VERSION ""

NS_ :

BS_:

BU_:

BO_ 3221225472 VECTOR__INDEPENDENT_SIG_MSG: 0 Vector__XXX
 SG_ OmegaX : 32|32@1- (1,0) [0|0] "rad" Vector__XXX
 SG_ volt2 : 15|16@0+ (0.1,0) [0|0] "mV" Vector__XXX
 SG_ volt3 : 31|16@0+ (0.1,0) [0|0] "mV" Vector__XXX
 SG_ volt4 : 46|16@0+ (0.1,0) [0|0] "mV" Vector__XXX
 SG_ NewSignal_0033 : 8|8@1+ (1,0) [0|0] "" Vector__XXX
 SG_ OmegaY : 0|32@1- (1,0) [0|0] "rad/s" Vector__XXX
 SG_ OmegaZ : 32|32@1- (1,0) [0|0] "rad/s" Vector__XXX
 SG_ AccZ : 0|32@1- (1,0) [0|0] "m/s^2" Vector__XXX
 SG_ OmegaX : 32|32@1- (1,0) [0|0] "rad/s" Vector__XXX
 SG_ AccX : 0|32@1- (1,0) [0|0] "m/s^2" Vector__XXX
 SG_ AccY : 32|32@1- (1,0) [0|0] "m/s^2" Vector__XXX
 SG_ SuspFL : 0|10@1+ (1,0) [0|0] "mm" Vector__XXX
 SG_ SuspFR : 10|10@1+ (1,0) [0|0] "mm" Vector__XXX
 SG_ SuspRL : 20|10@1+ (1,0) [0|0] "mm" Vector__XXX
 SG_ SuspRR : 30|10@1+ (1,0) [0|0] "mm" Vector__XXX
 SG_ Temp4 : 0|16@1+ (1,0) [0|0] "C" Vector__XXX
 SG_ Temp5 : 16|16@1+ (1,0) [0|0] "C" Vector__XXX
 SG_ Temp6 : 32|16@1+ (1,0) [0|0] "C" Vector__XXX
 SG_ Temp7 : 48|16@1+ (1,0) [0|0] "C" Vector__XXX
 SG_ Temp0 : 0|16@1+ (1,0) [0|0] "C" Vector__XXX
 SG_ Temp1 : 16|16@1+ (1,0) [0|0] "C" Vector__XXX
 SG_ Temp2 : 32|16@1+ (1,0) [0|0] "C" Vector__XXX
 SG_ Temp3 : 48|16@1+ (1,0) [0|0] "C" Vector__XXX

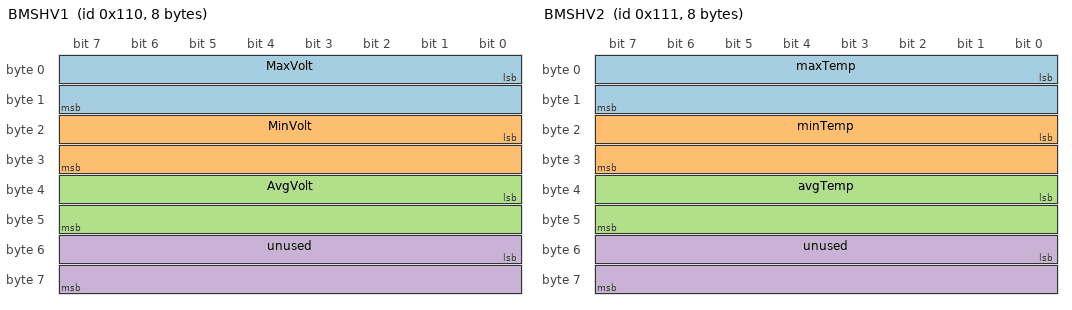
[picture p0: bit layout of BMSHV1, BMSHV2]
BO_ 272 BMSHV1: 8 Vector__XXX
 SG_ MaxVolt : 0|16@1+ (0.1,0) [0|0] "mV" Vector__XXX
 SG_ MinVolt : 16|16@1+ (0.1,0) [0|0] "mV" Vector__XXX
 SG_ AvgVolt : 32|16@1+ (0.1,0) [0|0] "mV" Vector__XXX
 SG_ unused : 48|16@1+ (1,0) [0|0] "" Vector__XXX

BO_ 273 BMSHV2: 8 Vector__XXX
 SG_ maxTemp : 0|16@1+ (1,0) [0|0] "C" Vector__XXX
 SG_ minTemp : 16|16@1+ (1,0) [0|0] "C" Vector__XXX
 SG_ avgTemp : 32|16@1+ (1,0) [0|0] "C" Vector__XXX
 SG_ unused : 48|16@1+ (1,0) [0|0] "" Vector__XXX

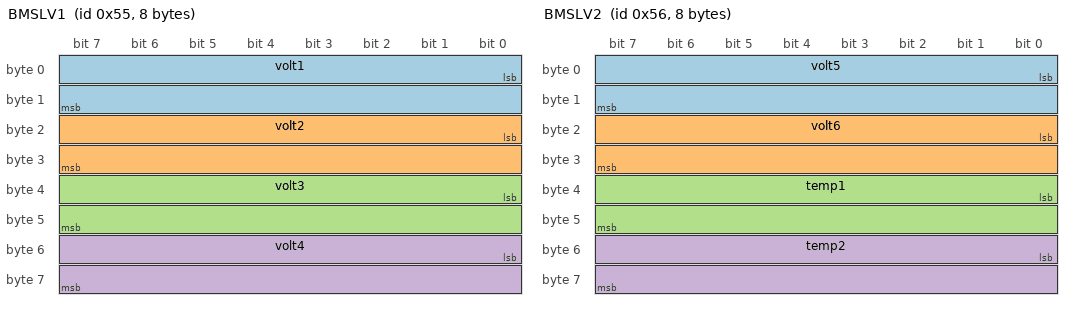
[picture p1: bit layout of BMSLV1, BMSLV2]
BO_ 85 BMSLV1: 8 Vector__XXX
 SG_ volt1 : 0|16@1+ (0.1,0) [0|0] "mV" Vector__XXX
 SG_ volt2 : 16|16@1+ (0.1,0) [0|0] "mV" Vector__XXX
 SG_ volt3 : 32|16@1+ (0.1,0) [0|0] "mV" Vector__XXX
 SG_ volt4 : 48|16@1+ (0.1,0) [0|0] "mV" Vector__XXX

BO_ 86 BMSLV2: 8 Vector__XXX
 SG_ volt5 : 0|16@1+ (0.1,0) [0|0] "mV" Vector__XXX
 SG_ volt6 : 16|16@1+ (0.1,0) [0|0] "mV" Vector__XXX
 SG_ temp1 : 32|16@1+ (0.001,0) [0|0] "C" Vector__XXX
 SG_ temp2 : 48|16@1+ (0.001,0) [0|0] "C" Vector__XXX

BO_ 962 LEM: 4 Vector__XXX
 SG_ curr : 7|32@0+ (1,0) [0|0] "mA" Vector__XXX

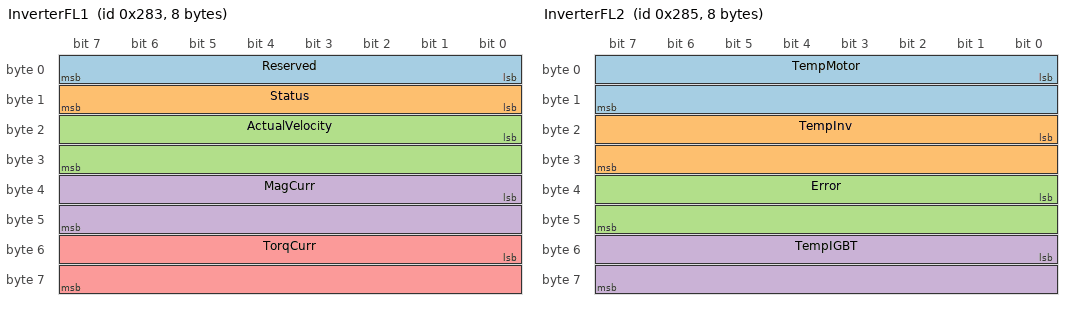
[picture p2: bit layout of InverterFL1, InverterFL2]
BO_ 643 InverterFL1: 8 Vector__XXX
 SG_ Reserved : 0|8@1+ (1,0) [0|0] "" Vector__XXX
 SG_ Status : 8|8@1+ (1,0) [0|0] "" Vector__XXX
 SG_ ActualVelocity : 16|16@1+ (1,0) [0|0] "" Vector__XXX
 SG_ MagCurr : 32|16@1+ (1,0) [0|0] "" Vector__XXX
 SG_ TorqCurr : 48|16@1+ (1,0) [0|0] "" Vector__XXX

BO_ 645 InverterFL2: 8 Vector__XXX
 SG_ TempMotor : 0|16@1+ (1,0) [0|0] "" Vector__XXX
 SG_ TempInv : 16|16@1+ (1,0) [0|0] "" Vector__XXX
 SG_ Error : 32|16@1+ (1,0) [0|0] "" Vector__XXX
 SG_ TempIGBT : 48|16@1+ (1,0) [0|0] "" Vector__XXX

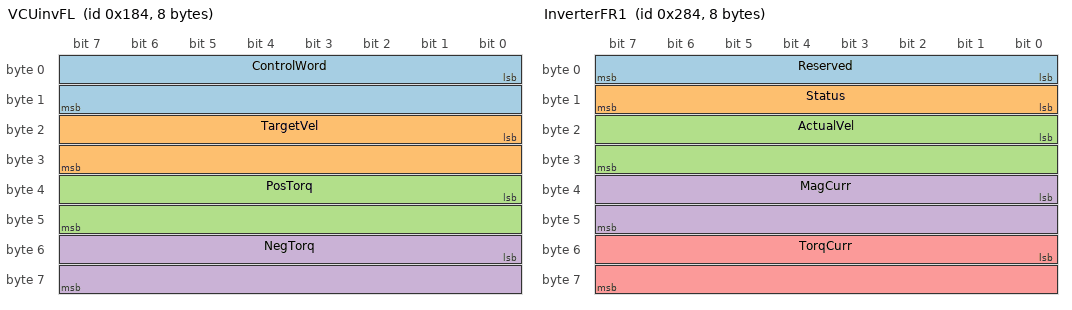
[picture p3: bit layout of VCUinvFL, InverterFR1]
BO_ 388 VCUinvFL: 8 Vector__XXX
 SG_ ControlWord : 0|16@1+ (1,0) [0|0] "" Vector__XXX
 SG_ TargetVel : 16|16@1+ (1,0) [0|0] "" Vector__XXX
 SG_ PosTorq : 32|16@1+ (1,0) [0|0] "" Vector__XXX
 SG_ NegTorq : 48|16@1+ (1,0) [0|0] "" Vector__XXX

BO_ 644 InverterFR1: 8 Vector__XXX
 SG_ Reserved : 0|8@1+ (1,0) [0|0] "" Vector__XXX
 SG_ Status : 8|8@1+ (1,0) [0|0] "" Vector__XXX
 SG_ ActualVel : 16|16@1+ (1,0) [0|0] "" Vector__XXX
 SG_ MagCurr : 32|16@1+ (1,0) [0|0] "" Vector__XXX
 SG_ TorqCurr : 48|16@1+ (1,0) [0|0] "" Vector__XXX

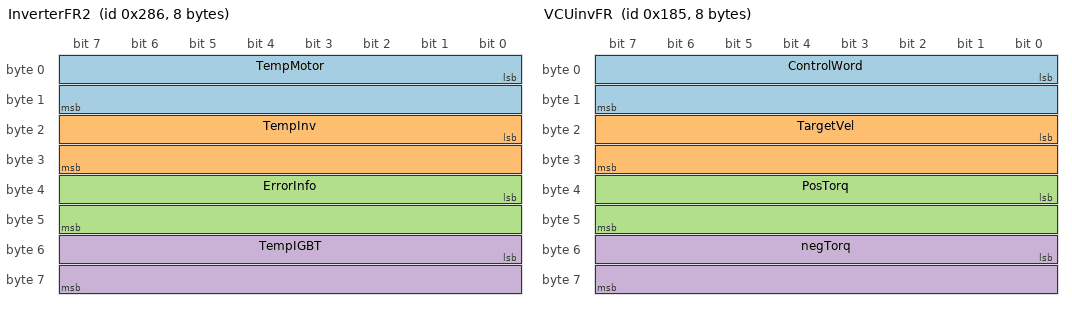
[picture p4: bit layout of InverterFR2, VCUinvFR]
BO_ 646 InverterFR2: 8 Vector__XXX
 SG_ TempMotor : 0|16@1+ (1,0) [0|0] "" Vector__XXX
 SG_ TempInv : 16|16@1+ (1,0) [0|0] "" Vector__XXX
 SG_ ErrorInfo : 32|16@1+ (1,0) [0|0] "" Vector__XXX
 SG_ TempIGBT : 48|16@1+ (1,0) [0|0] "" Vector__XXX

BO_ 389 VCUinvFR: 8 Vector__XXX
 SG_ ControlWord : 0|16@1+ (1,0) [0|0] "" Vector__XXX
 SG_ TargetVel : 16|16@1+ (1,0) [0|0] "" Vector__XXX
 SG_ PosTorq : 32|16@1+ (1,0) [0|0] "" Vector__XXX
 SG_ negTorq : 48|16@1+ (1,0) [0|0] "" Vector__XXX

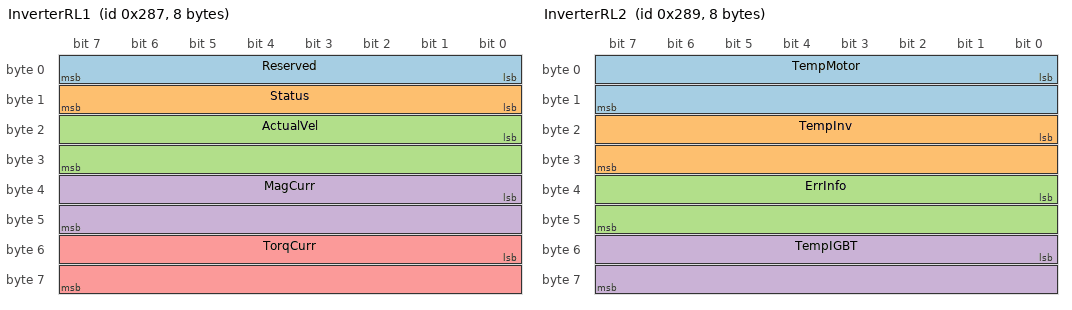
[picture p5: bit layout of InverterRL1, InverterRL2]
BO_ 647 InverterRL1: 8 Vector__XXX
 SG_ Reserved : 0|8@1+ (1,0) [0|0] "" Vector__XXX
 SG_ Status : 8|8@1+ (1,0) [0|0] "" Vector__XXX
 SG_ ActualVel : 16|16@1+ (1,0) [0|0] "" Vector__XXX
 SG_ MagCurr : 32|16@1+ (1,0) [0|0] "" Vector__XXX
 SG_ TorqCurr : 48|16@1+ (1,0) [0|0] "" Vector__XXX

BO_ 649 InverterRL2: 8 Vector__XXX
 SG_ TempMotor : 0|16@1+ (1,0) [0|0] "" Vector__XXX
 SG_ TempInv : 16|16@1+ (1,0) [0|0] "" Vector__XXX
 SG_ ErrInfo : 32|16@1+ (1,0) [0|0] "" Vector__XXX
 SG_ TempIGBT : 48|16@1+ (1,0) [0|0] "" Vector__XXX

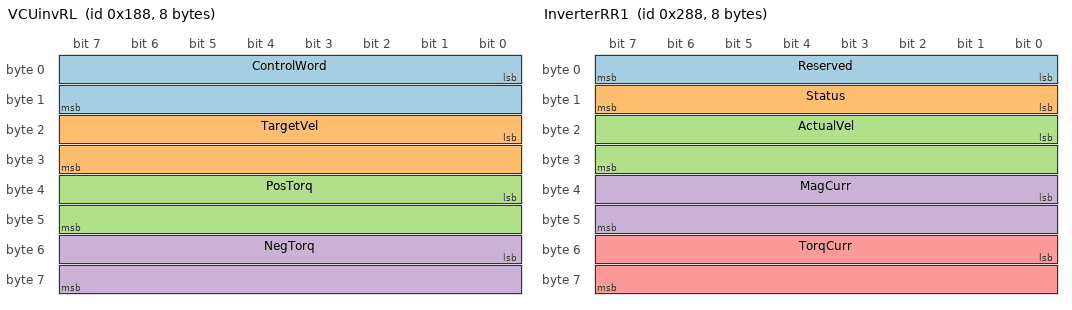
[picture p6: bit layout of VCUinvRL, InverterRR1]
BO_ 392 VCUinvRL: 8 Vector__XXX
 SG_ ControlWord : 0|16@1+ (1,0) [0|0] "" Vector__XXX
 SG_ TargetVel : 16|16@1+ (1,0) [0|0] "" Vector__XXX
 SG_ PosTorq : 32|16@1+ (1,0) [0|0] "" Vector__XXX
 SG_ NegTorq : 48|16@1+ (1,0) [0|0] "" Vector__XXX

BO_ 648 InverterRR1: 8 Vector__XXX
 SG_ Reserved : 0|8@1+ (1,0) [0|0] "" Vector__XXX
 SG_ Status : 8|8@1+ (1,0) [0|0] "" Vector__XXX
 SG_ ActualVel : 16|16@1+ (1,0) [0|0] "" Vector__XXX
 SG_ MagCurr : 32|16@1+ (1,0) [0|0] "" Vector__XXX
 SG_ TorqCurr : 48|16@1+ (1,0) [0|0] "" Vector__XXX

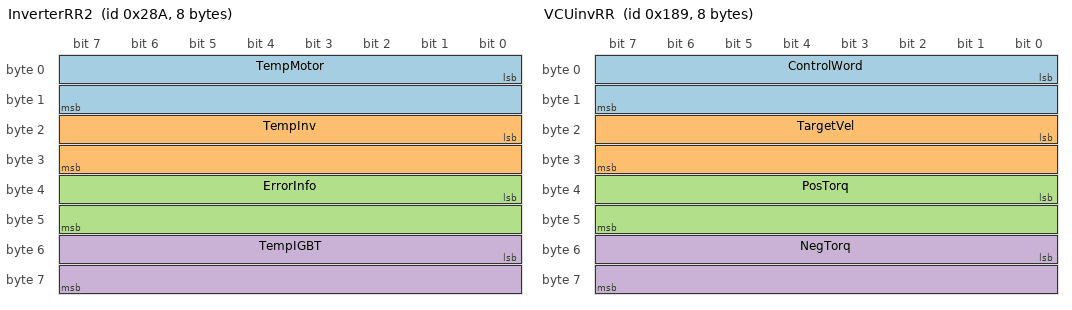
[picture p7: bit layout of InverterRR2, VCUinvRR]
BO_ 650 InverterRR2: 8 Vector__XXX
 SG_ TempMotor : 0|16@1+ (1,0) [0|0] "" Vector__XXX
 SG_ TempInv : 16|16@1+ (1,0) [0|0] "" Vector__XXX
 SG_ ErrorInfo : 32|16@1+ (1,0) [0|0] "" Vector__XXX
 SG_ TempIGBT : 48|16@1+ (1,0) [0|0] "" Vector__XXX

BO_ 393 VCUinvRR: 8 Vector__XXX
 SG_ ControlWord : 0|16@1+ (1,0) [0|0] "" Vector__XXX
 SG_ TargetVel : 16|16@1+ (1,0) [0|0] "" Vector__XXX
 SG_ PosTorq : 32|16@1+ (1,0) [0|0] "" Vector__XXX
 SG_ NegTorq : 48|16@1+ (1,0) [0|0] "" Vector__XXX

BO_ 96 IMU1: 8 Vector__XXX
 SG_ AccX : 0|32@1- (1,0) [0|0] "m/s^2" Vector__XXX
 SG_ AccY : 32|32@1- (1,0) [0|0] "m/s^2" Vector__XXX

BO_ 97 IMU2: 8 Vector__XXX
 SG_ AccZ : 0|32@1- (1,0) [0|0] "m/s^2" Vector__XXX
 SG_ OmegaX : 32|32@1- (1,0) [0|0] "rad/s" Vector__XXX

BO_ 98 IMU3: 8 Vector__XXX
 SG_ OmegaY : 0|32@1- (1,0) [0|0] "rad/s" Vector__XXX
 SG_ OmegaZ : 32|32@1- (1,0) [0|0] "rad/s" Vector__XXX

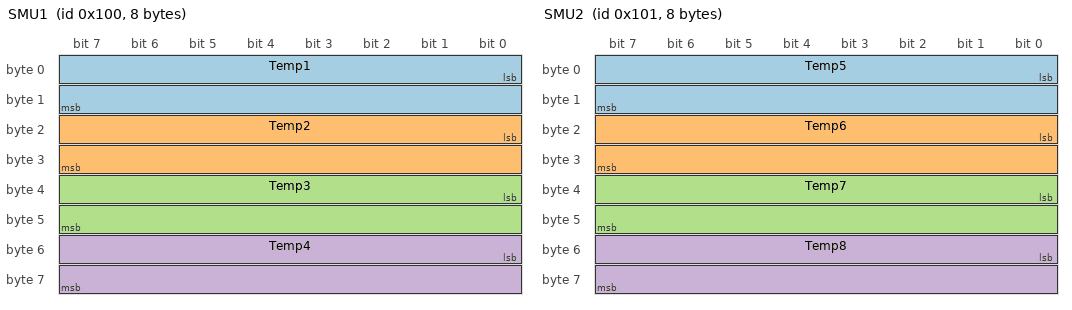
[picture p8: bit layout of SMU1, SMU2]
BO_ 256 SMU1: 8 Vector__XXX
 SG_ Temp1 : 0|16@1+ (1,0) [0|0] "C" Vector__XXX
 SG_ Temp2 : 16|16@1+ (1,0) [0|0] "C" Vector__XXX
 SG_ Temp3 : 32|16@1+ (1,0) [0|0] "C" Vector__XXX
 SG_ Temp4 : 48|16@1+ (1,0) [0|0] "C" Vector__XXX

BO_ 257 SMU2: 8 Vector__XXX
 SG_ Temp5 : 0|16@1+ (1,0) [0|0] "C" Vector__XXX
 SG_ Temp6 : 16|16@1+ (1,0) [0|0] "C" Vector__XXX
 SG_ Temp7 : 32|16@1+ (1,0) [0|0] "C" Vector__XXX
 SG_ Temp8 : 48|16@1+ (1,0) [0|0] "C" Vector__XXX

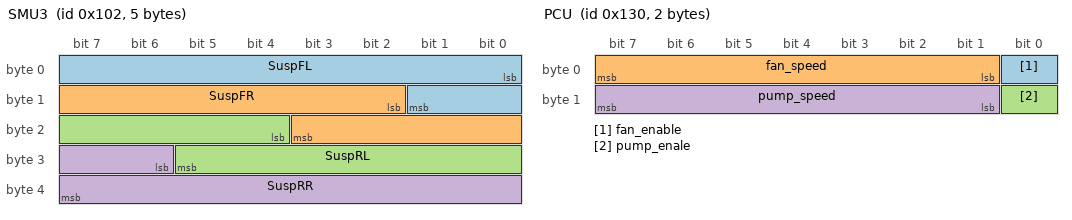
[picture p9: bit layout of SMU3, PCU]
BO_ 258 SMU3: 5 Vector__XXX
 SG_ SuspFL : 0|10@1+ (1,0) [0|0] "mm" Vector__XXX
 SG_ SuspFR : 10|10@1+ (1,0) [0|0] "mm" Vector__XXX
 SG_ SuspRL : 20|10@1+ (1,0) [0|0] "mm" Vector__XXX
 SG_ SuspRR : 30|10@1+ (1,0) [0|0] "mm" Vector__XXX

BO_ 288 INV_VOLT: 4 Vector__XXX
 SG_ car_voltage : 0|16@1+ (1,0) [0|0] "V" Vector__XXX

BO_ 304 PCU: 2 Vector__XXX
 SG_ fan_enable : 0|1@1+ (1,0) [0|0] "on" Vector__XXX
 SG_ fan_speed : 1|7@1+ (1,0) [0|0] "%" Vector__XXX
 SG_ pump_enale : 8|1@1+ (1,0) [0|0] "on" Vector__XXX
 SG_ pump_speed : 9|7@1+ (1,0) [0|0] "%" Vector__XXX

CM_ SG_ 3221225472 OmegaY "Pitch";
CM_ SG_ 3221225472 AccZ "Z Acceleration";
CM_ SG_ 3221225472 AccX "X acceleration";
CM_ SG_ 3221225472 AccY "Y Acceleration
";
BA_DEF_ BO_  "VFrameFormat" ENUM  "StandardCAN","ExtendedCAN","reserved","J1939PG";
BA_DEF_  "DatabaseVersion" STRING ;
BA_DEF_  "BusType" STRING ;
BA_DEF_  "ProtocolType" STRING ;
BA_DEF_  "DatabaseCompiler" STRING ;
BA_DEF_DEF_  "VFrameFormat" "J1939PG";
BA_DEF_DEF_  "DatabaseVersion" "DEMO PLUS";
BA_DEF_DEF_  "BusType" "";
BA_DEF_DEF_  "ProtocolType" "";
BA_DEF_DEF_  "DatabaseCompiler" "";
BA_ "ProtocolType" "J1939";
BA_ "BusType" "CAN";
BA_ "DatabaseCompiler" "CSS ELECTRONICS (WWW.CSSELECTRONICS.COM)";
BA_ "DatabaseVersion" "1.0.0";
BA_ "VFrameFormat" BO_ 272 0;
BA_ "VFrameFormat" BO_ 273 0;
BA_ "VFrameFormat" BO_ 85 0;
BA_ "VFrameFormat" BO_ 86 0;
BA_ "VFrameFormat" BO_ 962 0;
BA_ "VFrameFormat" BO_ 643 0;
BA_ "VFrameFormat" BO_ 645 0;
BA_ "VFrameFormat" BO_ 388 0;
BA_ "VFrameFormat" BO_ 644 0;
BA_ "VFrameFormat" BO_ 646 0;
BA_ "VFrameFormat" BO_ 389 0;
BA_ "VFrameFormat" BO_ 647 0;
BA_ "VFrameFormat" BO_ 649 0;
BA_ "VFrameFormat" BO_ 392 0;
BA_ "VFrameFormat" BO_ 648 0;
BA_ "VFrameFormat" BO_ 650 0;
BA_ "VFrameFormat" BO_ 393 0;
BA_ "VFrameFormat" BO_ 96 0;
BA_ "VFrameFormat" BO_ 97 0;
BA_ "VFrameFormat" BO_ 98 0;
BA_ "VFrameFormat" BO_ 256 0;
BA_ "VFrameFormat" BO_ 257 0;
BA_ "VFrameFormat" BO_ 258 0;
BA_ "VFrameFormat" BO_ 288 0;
BA_ "VFrameFormat" BO_ 304 0;
SIG_VALTYPE_ 96 AccX : 1;
SIG_VALTYPE_ 96 AccY : 1;
SIG_VALTYPE_ 97 AccZ : 1;
SIG_VALTYPE_ 97 OmegaX : 1;
SIG_VALTYPE_ 98 OmegaY : 1;
SIG_VALTYPE_ 98 OmegaZ : 1;
